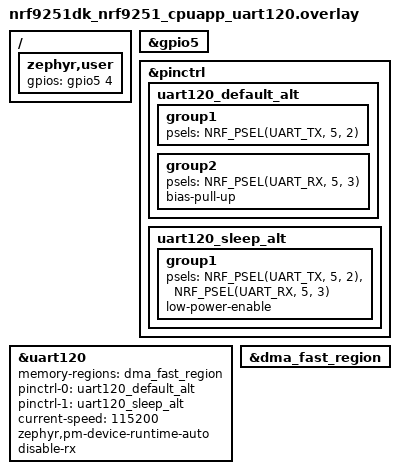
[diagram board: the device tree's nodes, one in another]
/*
 * Test requires wire connection between:
 *  - uart120 TX at P5.02 <-> GPIO input at P5.04
 */

/ {
	zephyr,user {
		gpios = <&gpio5 4 GPIO_ACTIVE_HIGH>;
	};
};

&gpio5 {
	status = "okay";
};

&pinctrl {
	uart120_default_alt: uart120_default_alt {
		group1 {
			psels = <NRF_PSEL(UART_TX, 5, 2)>;
		};

		group2 {
			psels = <NRF_PSEL(UART_RX, 5, 3)>;
			bias-pull-up;
		};
	};

	uart120_sleep_alt: uart120_sleep_alt {
		group1 {
			psels = <NRF_PSEL(UART_TX, 5, 2)>,
				<NRF_PSEL(UART_RX, 5, 3)>;
			low-power-enable;
		};
	};
};

dut: &uart120 {
	status = "okay";
	memory-regions = <&dma_fast_region>;
	pinctrl-0 = <&uart120_default_alt>;
	pinctrl-1 = <&uart120_sleep_alt>;
	pinctrl-names = "default", "sleep";
	current-speed = <115200>;
	zephyr,pm-device-runtime-auto;
	disable-rx;
};

&dma_fast_region {
	status = "okay";
};
